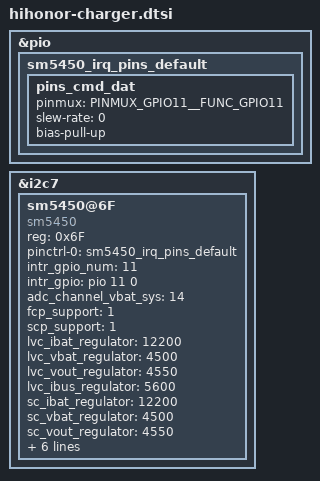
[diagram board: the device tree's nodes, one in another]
#include "../hihonor_charger/mt6833_cma_22p5w_honor_charger.dtsi"

&pio {
	sm5450_irq_pins_default: sm5450_irq_pins_default {
		pins_cmd_dat {
			pinmux = <PINMUX_GPIO11__FUNC_GPIO11>;
			slew-rate = <0>;
			bias-pull-up;
		};
	};
};

&i2c7 {
	sm5450@6F{
		compatible = "sm5450";
		reg = <0x6F>;
		pinctrl-names = "default";
		pinctrl-0 = <&sm5450_irq_pins_default>;
		intr_gpio_num = <11>; /* direct defined GPIO num */
		intr_gpio = <&pio 11 0>;
		adc_channel_vbat_sys = <14>;
		fcp_support = <1>;
		scp_support = <1>;
		lvc_ibat_regulator = <12200>;
		lvc_vbat_regulator = <4500>;
		lvc_vout_regulator = <4550>;
		lvc_ibus_regulator = <5600>;
		sc_ibat_regulator = <12200>;
		sc_vbat_regulator = <4500>;
		sc_vout_regulator = <4550>;
		sc_ibus_regulator = <5600>;
		lvc_vusb2vbus_drop_en = <1>;
		sc_vusb2vbus_drop_en = <1>;
		bat_comp = <30>;
		vclamp = <90>;
		r_coul_mohm = <2>;
		status = "ok";
	};
};
